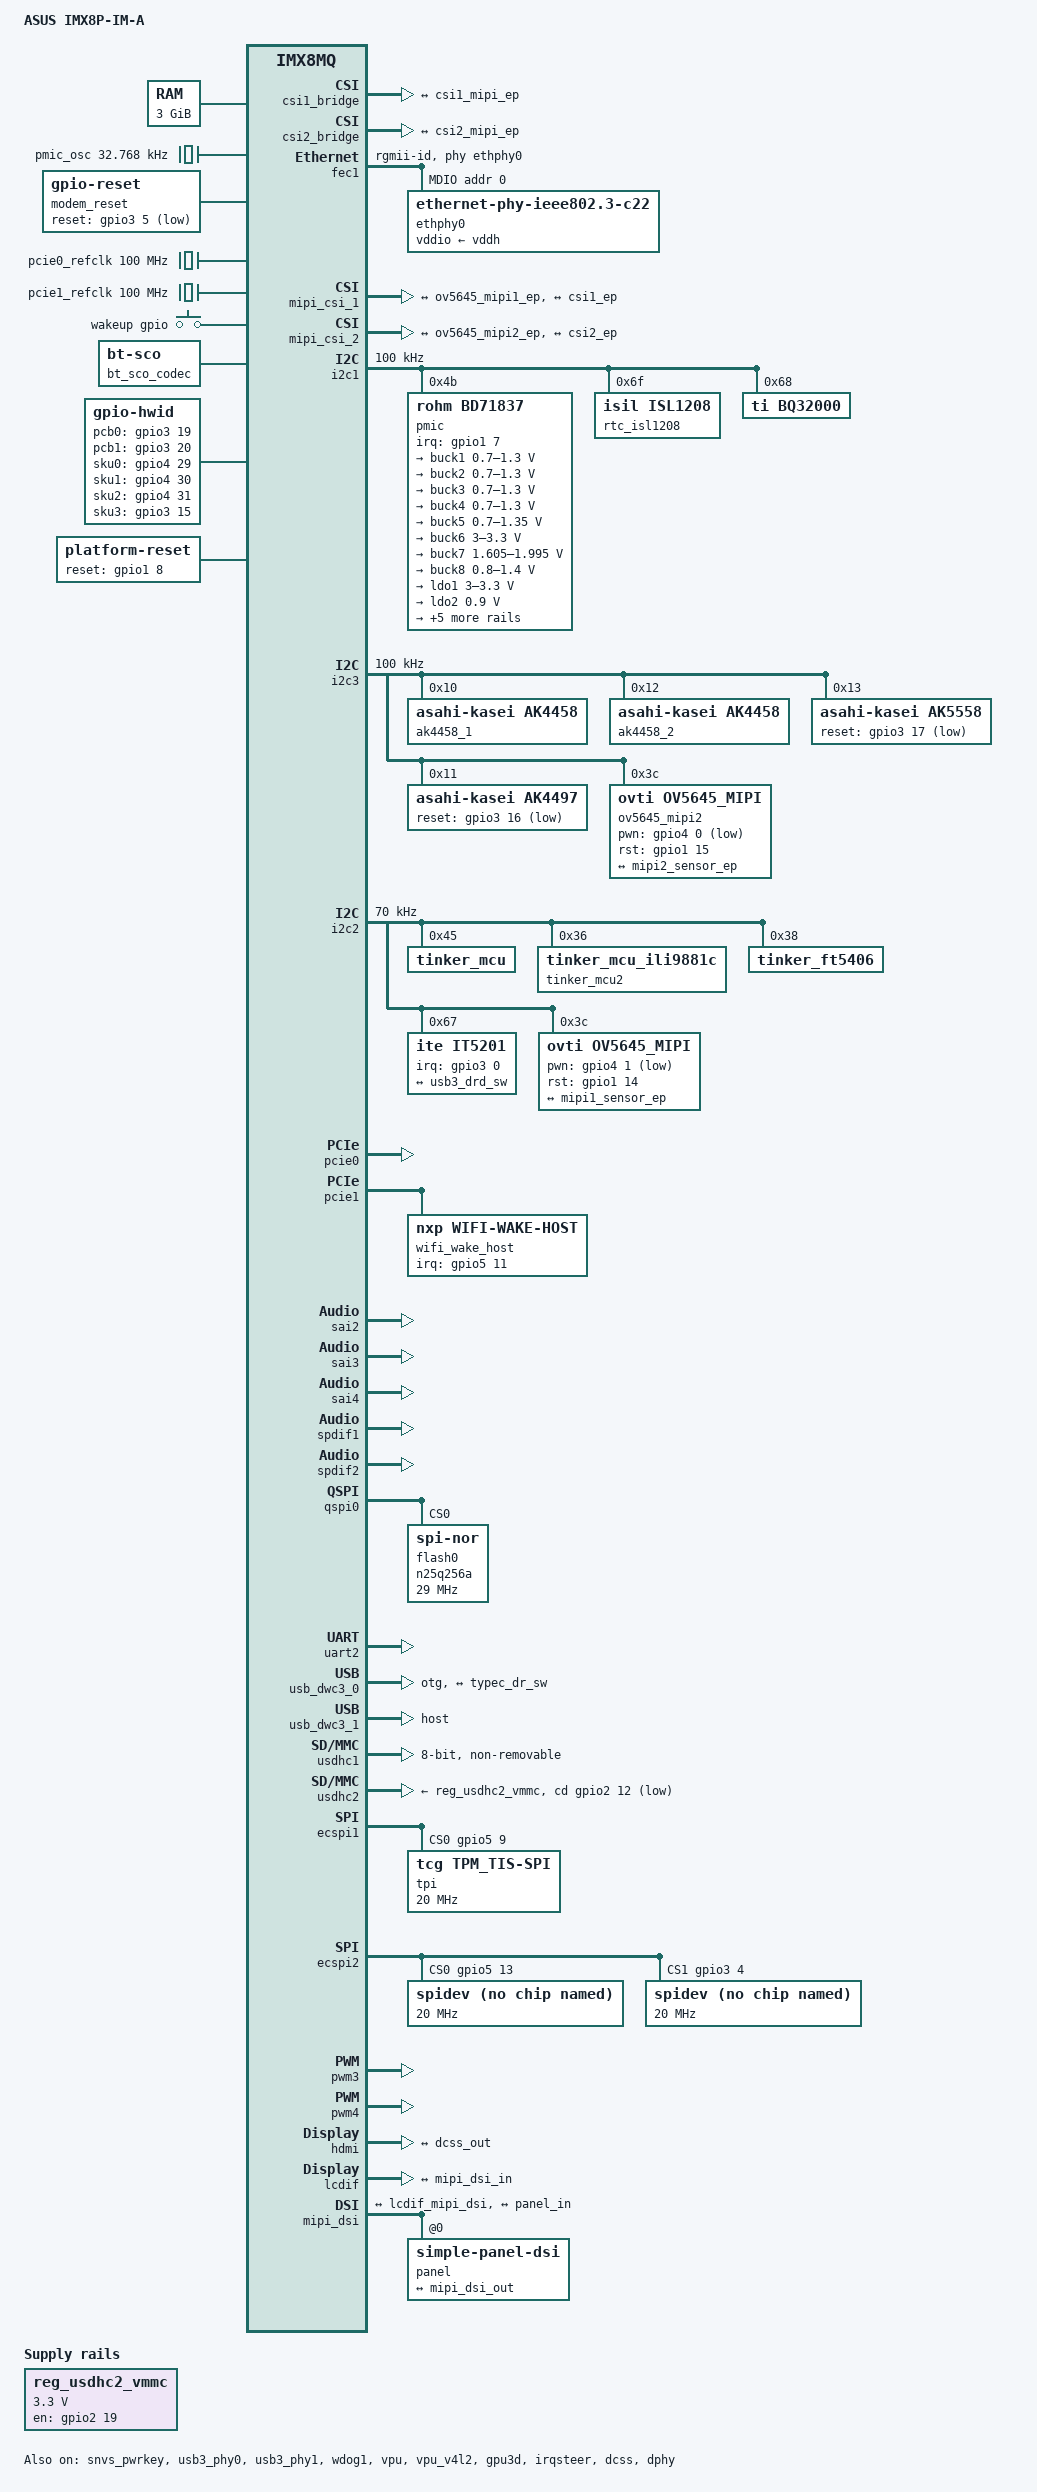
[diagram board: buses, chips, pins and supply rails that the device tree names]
// SPDX-License-Identifier: (GPL-2.0 OR MIT)
/*
 * Copyright 2017 NXP
 * Copyright (C) 2017-2018 Pengutronix, Lucas Stach <kernel@pengutronix.de>
 */

/dts-v1/;

#include <dt-bindings/usb/pd.h>
#include "imx8mq.dtsi"

/ {
	model = "ASUS IMX8P-IM-A";
	compatible = "fsl,imx8mq-evk", "fsl,imx8mq";

        aliases {
                rtc0 = &snvs_rtc;
                rtc1 = &bq32000;
                rtc2 = &rtc_isl1208;
        };

	chosen {
		stdout-path = &uart1;
	};

	memory@40000000 {
		device_type = "memory";
		reg = <0x00000000 0x40000000 0 0xc0000000>;
	};

	pmic_osc: clock-pmic {
		compatible = "fixed-clock";
		#clock-cells = <0>;
		clock-frequency = <32768>;
		clock-output-names = "pmic_osc";
	};

	modem_reset: modem-reset {
		compatible = "gpio-reset";
		reset-gpios = <&gpio3 5 GPIO_ACTIVE_LOW>;
		reset-delay-us = <2000>;
		reset-post-delay-ms = <40>;
		#reset-cells = <0>;
	};

	resmem: reserved-memory {
		#address-cells = <2>;
		#size-cells = <2>;
		ranges;

		/* global autoconfigured region for contiguous allocations */
		linux,cma {
			compatible = "shared-dma-pool";
			reusable;
			size = <0 0x38000000>;
			alloc-ranges = <0 0x80000000 0 0x38000000>;
			linux,cma-default;
		};
	};

	pcie0_refclk: pcie0-refclk {
		compatible = "fixed-clock";
		#clock-cells = <0>;
		clock-frequency = <100000000>;
	};

	pcie1_refclk: pcie0-refclk {
		compatible = "fixed-clock";
		#clock-cells = <0>;
		clock-frequency = <100000000>;
	};

	reg_usdhc2_vmmc: regulator-vsd-3v3 {
		pinctrl-names = "default";
		pinctrl-0 = <&pinctrl_reg_usdhc2>;
		compatible = "regulator-fixed";
		regulator-name = "VSD_3V3";
		regulator-min-microvolt = <3300000>;
		regulator-max-microvolt = <3300000>;
		gpio = <&gpio2 19 GPIO_ACTIVE_HIGH>;
		off-on-delay-us = <20000>;
		enable-active-high;
	};

	gpio-keys {
		compatible = "gpio-keys";
		wakeup {
			label = "wakeup gpio";
			gpio = <&gpio1 12 GPIO_ACTIVE_LOW>;
			linux,code = <KEY_WAKEUP>;
			gpio-key,wakeup;
		};
	};

	ir-receiver {
		compatible = "gpio-ir-receiver";
		gpios = <&gpio1 12 GPIO_ACTIVE_LOW>;
		pinctrl-names = "default";
		pinctrl-0 = <&pinctrl_ir>;
		linux,autosuspend-period = <125>;
		status = "disabled";
	};

	bt_sco_codec: bt_sco_codec {
		#sound-dai-cells = <1>;
		compatible = "linux,bt-sco";
	};

	wm8524: audio-codec {
		#sound-dai-cells = <0>;
		compatible = "wlf,wm8524";
		wlf,mute-gpios = <&gpio1 8 GPIO_ACTIVE_LOW>;
		status = "disabled";
	};

	sound-bt-sco {
		compatible = "simple-audio-card";
		simple-audio-card,name = "bt-sco-audio";
		simple-audio-card,format = "dsp_a";
		simple-audio-card,bitclock-inversion;
		simple-audio-card,frame-master = <&btcpu>;
		simple-audio-card,bitclock-master = <&btcpu>;

		btcpu: simple-audio-card,cpu {
			sound-dai = <&sai3>;
			dai-tdm-slot-num = <2>;
			dai-tdm-slot-width = <16>;
		};

		simple-audio-card,codec {
			sound-dai = <&bt_sco_codec 1>;
		};
	};

	sound-wm8524 {
		compatible = "simple-audio-card";
		simple-audio-card,name = "wm8524-audio";
		simple-audio-card,format = "i2s";
		simple-audio-card,frame-master = <&cpudai>;
		simple-audio-card,bitclock-master = <&cpudai>;
		simple-audio-card,widgets =
			"Line", "Left Line Out Jack",
			"Line", "Right Line Out Jack";
		simple-audio-card,routing =
			"Left Line Out Jack", "LINEVOUTL",
			"Right Line Out Jack", "LINEVOUTR";

		cpudai: simple-audio-card,cpu {
			sound-dai = <&sai2>;
			dai-tdm-slot-num = <2>;
			dai-tdm-slot-width = <32>;
		};

		link_codec: simple-audio-card,codec {
			sound-dai = <&wm8524>;
			clocks = <&clk IMX8MQ_CLK_SAI2_ROOT>;
		};
	};

	sound-hdmi {
		compatible = "fsl,imx-audio-hdmi";
		model = "imx-audio-hdmi";
		audio-cpu = <&sai4>;
		hdmi-out;
		constraint-rate = <44100>,
				<88200>,
				<176400>,
				<32000>,
				<48000>,
				<96000>,
				<192000>;
	};

	sound-spdif {
		compatible = "fsl,imx-audio-spdif";
		model = "imx-spdif";
		spdif-controller = <&spdif1>;
		spdif-out;
		spdif-in;
	};

	sound-hdmi-arc {
		compatible = "fsl,imx-audio-spdif";
		model = "imx-hdmi-arc";
		spdif-controller = <&spdif2>;
		spdif-in;
	};

	sound-ak4458 {
		compatible = "fsl,imx-audio-card";
		model = "ak4458-audio";
		pri-dai-link {
			link-name = "akcodec";
			format = "i2s";
			cpu {
				sound-dai = <&sai1>;
			};
			codec {
				sound-dai = <&ak4458_1>, <&ak4458_2>;
			};
		};
	};

	sound-ak5558 {
		compatible = "fsl,imx-audio-card";
		model = "ak5558-audio";
		pri-dai-link {
			link-name = "akcodec";
			format = "i2s";
			cpu {
				sound-dai = <&sai5>;
			};
			codec {
				sound-dai = <&ak5558>;
			};
		};
	};

	sound-ak4497 {
		compatible = "fsl,imx-audio-card";
		model = "ak4497-audio";
		status = "disabled";
		pri-dai-link {
			link-name = "akcodec";
			format = "i2s";
			cpu {
				sound-dai = <&sai1>;
			};
			codec {
				sound-dai = <&ak4497>;
			};
		};
	};

	hwid: gpio-hwid {
		compatible = "gpio-hwid";
		boardinfo = "IMX8P-IM-A";
		pcb0-gpios = <&gpio3 19 GPIO_ACTIVE_HIGH>;
		pcb1-gpios = <&gpio3 20 GPIO_ACTIVE_HIGH>;
		sku0-gpios = <&gpio4 29 GPIO_ACTIVE_HIGH>;
		sku1-gpios = <&gpio4 30 GPIO_ACTIVE_HIGH>;
		sku2-gpios = <&gpio4 31 GPIO_ACTIVE_HIGH>;
		sku3-gpios = <&gpio3 15 GPIO_ACTIVE_HIGH>;
	};
	
	platform-reset {
		compatible = "platform-reset";
		reset-gpio = <&gpio1 8 GPIO_ACTIVE_HIGH>;
	};

	backlight_dsi: backlight_dsi {
		compatible = "pwm-backlight";
		pwms = <&pwm4 0 400000>;
		status = "disabled";
		pinctrl-names = "default";
		pinctrl-0 = <&pinctrl_dsi>;
		soc_enablekl-gpios = <&gpio3 24 GPIO_ACTIVE_HIGH>;
		default-brightness-level = <200>;
		minimal-brightness-level = <30>;

		brightness-levels = <
				0   1   2   3   4   5   6   7
				8   9   10  11  12  13  14  15
				16  17  18  19  20  21  22  23
				24  25  26  27  28  29  30  31
				32  33  34  35  36  37  38  39
				40  41  42  43  44  45  46  47
				48  49  50  51  52  53  54  55
				56  57  58  59  60  61  62  63
				64  65  66  67  68  69  70  71
				72  73  74  75  76  77  78  79
				80  81  82  83  84  85  86  87
				88  89  90  91  92  93  94  95
				96  97  98  99  100 101 102 103
				104 105 106 107 108 109 110 111
				112 113 114 115 116 117 118 119
				120 121 122 123 124 125 126 127
				128 129 130 131 132 133 134 135
				136 137 138 139 140 141 142 143
				144 145 146 147 148 149 150 151
				152 153 154 155 156 157 158 159
				160 161 162 163 164 165 166 167
				168 169 170 171 172 173 174 175
				176 177 178 179 180 181 182 183
				184 185 186 187 188 189 190 191
				192 193 194 195 196 197 198 199
				200 201 202 203 204 205 206 207
				208 209 210 211 212 213 214 215
				216 217 218 219 220 221 222 223
				224 225 226 227 228 229 230 231
				232 233 234 235 236 237 238 239
				240 241 242 243 244 245 246 247
				248 249 250 251 252 253 254 255
		>;
	};
};

&ocotp {
	read-only;
};

&A53_0 {
	cpu-supply = <&buck2>;
};

&A53_1 {
	cpu-supply = <&buck2>;
};

&A53_2 {
	cpu-supply = <&buck2>;
};

&A53_3 {
	cpu-supply = <&buck2>;
};

&csi1_bridge {
	fsl,mipi-mode;
	fsl,two-8bit-sensor-mode;
	status = "okay";

	port {
		csi1_ep: endpoint {
			remote-endpoint = <&csi1_mipi_ep>;
		};
	};
};

&csi2_bridge {
	fsl,mipi-mode;
	fsl,two-8bit-sensor-mode;
	status = "okay";

	port {
		csi2_ep: endpoint {
			remote-endpoint = <&csi2_mipi_ep>;
		};
	};
};

&ddrc {
	operating-points-v2 = <&ddrc_opp_table>;

	ddrc_opp_table: opp-table {
		compatible = "operating-points-v2";

		opp-25M {
			opp-hz = /bits/ 64 <25000000>;
		};

		opp-100M {
			opp-hz = /bits/ 64 <100000000>;
		};

		/*
		 * On imx8mq B0 PLL can't be bypassed so low bus is 166M
		 */
		opp-166M {
			opp-hz = /bits/ 64 <166935483>;
		};

		opp-800M {
			opp-hz = /bits/ 64 <800000000>;
		};
	};
};

&fec1 {
	pinctrl-names = "default";
	pinctrl-0 = <&pinctrl_fec1>;
	phy-mode = "rgmii-id";
	phy-handle = <&ethphy0>;
	fsl,magic-packet;
	status = "okay";

	mdio {
		#address-cells = <1>;
		#size-cells = <0>;

		ethphy0: ethernet-phy@0 {
			compatible = "ethernet-phy-ieee802.3-c22";
			reg = <0>;
			qca,disable-smarteee;
			vddio-supply = <&vddh>;

			vddh: vddh-regulator {
			};
		};
	};
};

&mipi_csi_1 {
	#address-cells = <1>;
	#size-cells = <0>;
	status = "okay";
	port {
		mipi1_sensor_ep: endpoint@0 {
			remote-endpoint = <&ov5645_mipi1_ep>;
			data-lanes = <1 2>;
			bus-type = <4>;
		};

		csi1_mipi_ep: endpoint@1 {
			remote-endpoint = <&csi1_ep>;
		};
	};
};

&mipi_csi_2 {
	#address-cells = <1>;
	#size-cells = <0>;
	status = "okay";
	port {
		mipi2_sensor_ep: endpoint@0 {
			remote-endpoint = <&ov5645_mipi2_ep>;
			data-lanes = <1 2>;
			bus-type = <4>;
		};

		csi2_mipi_ep: endpoint@1 {
			remote-endpoint = <&csi2_ep>;
		};
	};
};

&i2c1 {
	clock-frequency = <100000>;
	pinctrl-names = "default";
	pinctrl-0 = <&pinctrl_i2c1>;
	status = "okay";

	ov5640_mipi2: ov5640_mipi2@3c {
		compatible = "ovti,ov5640_mipi";
		reg = <0x3c>;
		status = "disabled";
		pinctrl-names = "default";
		pinctrl-0 = <&pinctrl_csi2_pwn>, <&pinctrl_csi_rst>;
		clocks = <&clk IMX8MQ_CLK_CLKO2>;
		clock-names = "csi_mclk";
		assigned-clocks = <&clk IMX8MQ_CLK_CLKO2>;
		assigned-clock-parents = <&clk IMX8MQ_SYS2_PLL_200M>;
		assigned-clock-rates = <20000000>;
		csi_id = <1>;
		pwn-gpios = <&gpio1 5 GPIO_ACTIVE_HIGH>;
		mclk = <20000000>;
		mclk_source = <0>;
		port {
			ov5640_mipi2_ep: endpoint {
				remote-endpoint = <&mipi2_sensor_ep>;
			};
		};
	};

	pmic: bd71837@4b {
		compatible = "rohm,bd71837";
		reg = <0x4b>;
		pinctrl-names = "default";
		pinctrl-0 = <&pinctrl_pmic>;
		#clock-cells = <0>;
		clocks = <&pmic_osc>;
		clock-output-names = "pmic_clk";
		interrupt-parent = <&gpio1>;
		interrupts = <7 IRQ_TYPE_LEVEL_LOW>;
		rohm,reset-snvs-powered;

		regulators {
			buck1: BUCK1 {
				regulator-name = "buck1";
				regulator-min-microvolt = <700000>;
				regulator-max-microvolt = <1300000>;
				regulator-boot-on;
				regulator-always-on;
				regulator-ramp-delay = <1250>;
			};

			buck2: BUCK2 {
				regulator-name = "buck2";
				regulator-min-microvolt = <700000>;
				regulator-max-microvolt = <1300000>;
				regulator-boot-on;
				regulator-always-on;
			};

			buck3: BUCK3 {
				regulator-name = "buck3";
				regulator-min-microvolt = <700000>;
				regulator-max-microvolt = <1300000>;
				regulator-boot-on;
			};

			buck4: BUCK4 {
				regulator-name = "buck4";
				regulator-min-microvolt = <700000>;
				regulator-max-microvolt = <1300000>;
				regulator-boot-on;
				regulator-always-on;
			};

			buck5: BUCK5 {
				regulator-name = "buck5";
				regulator-min-microvolt = <700000>;
				regulator-max-microvolt = <1350000>;
				regulator-boot-on;
				regulator-always-on;
			};

			buck6: BUCK6 {
				regulator-name = "buck6";
				regulator-min-microvolt = <3000000>;
				regulator-max-microvolt = <3300000>;
				regulator-boot-on;
				regulator-always-on;
			};

			buck7: BUCK7 {
				regulator-name = "buck7";
				regulator-min-microvolt = <1605000>;
				regulator-max-microvolt = <1995000>;
				regulator-boot-on;
				regulator-always-on;
			};

			buck8: BUCK8 {
				regulator-name = "buck8";
				regulator-min-microvolt = <800000>;
				regulator-max-microvolt = <1400000>;
				regulator-boot-on;
				regulator-always-on;
			};

			ldo1: LDO1 {
				regulator-name = "ldo1";
				regulator-min-microvolt = <3000000>;
				regulator-max-microvolt = <3300000>;
				regulator-boot-on;
				regulator-always-on;
			};

			ldo2: LDO2 {
				regulator-name = "ldo2";
				regulator-min-microvolt = <900000>;
				regulator-max-microvolt = <900000>;
				regulator-boot-on;
				regulator-always-on;
			};

			ldo3: LDO3 {
				regulator-name = "ldo3";
				regulator-min-microvolt = <1800000>;
				regulator-max-microvolt = <3300000>;
				regulator-boot-on;
				regulator-always-on;
			};

			ldo4: LDO4 {
				regulator-name = "ldo4";
				regulator-min-microvolt = <900000>;
				regulator-max-microvolt = <1800000>;
				regulator-boot-on;
				regulator-always-on;
			};

			ldo5: LDO5 {
				regulator-name = "ldo5";
				regulator-min-microvolt = <1800000>;
				regulator-max-microvolt = <3300000>;
				regulator-boot-on;
				regulator-always-on;
			};

			ldo6: LDO6 {
				regulator-name = "ldo6";
				regulator-min-microvolt = <900000>;
				regulator-max-microvolt = <1800000>;
				regulator-boot-on;
				regulator-always-on;
			};

			ldo7: LDO7 {
				regulator-name = "ldo7";
				regulator-min-microvolt = <1800000>;
				regulator-max-microvolt = <3300000>;
				regulator-boot-on;
				regulator-always-on;
			};
		};
	};

	rtc_isl1208: rtc@6f {
		compatible = "isil,isl1208";
		reg = <0x6f>;
		status = "okay";
	};

        bq32000: rtc@68 {
                compatible = "ti,bq32000";
                reg = <0x68>;
        };
};

&i2c3 {
	clock-frequency = <100000>;
	pinctrl-names = "default";
	pinctrl-0 = <&pinctrl_i2c3>;
	status = "okay";

	synaptics_dsx_ts: synaptics_dsx_ts@20 {
		compatible = "synaptics_dsx";
		reg = <0x20>;
		pinctrl-names = "default";
		pinctrl-0 = <&pinctrl_i2c1_dsi_ts_int>;
		interrupt-parent = <&gpio5>;
		interrupts = <7 IRQ_TYPE_LEVEL_LOW>;
		synaptics,diagonal-rotation;
		status = "disabled";
	};

	ak4458_1: ak4458@10 {
		#sound-dai-cells = <0>;
		sound-name-prefix = "0";
		compatible = "asahi-kasei,ak4458";
		reg = <0x10>;
	};

	ak4458_2: ak4458@12 {
		#sound-dai-cells = <0>;
		sound-name-prefix = "1";
		compatible = "asahi-kasei,ak4458";
		reg = <0x12>;
	};

	ak5558: ak5558@13 {
		#sound-dai-cells = <0>;
		compatible = "asahi-kasei,ak5558";
		reg = <0x13>;
		reset-gpios = <&gpio3 17 GPIO_ACTIVE_LOW>;
	};

	ak4497: ak4497@11 {
		#sound-dai-cells = <0>;
		compatible = "asahi-kasei,ak4497";
		reg = <0x11>;
		reset-gpios = <&gpio3 16 GPIO_ACTIVE_LOW>;
		dsd-path = <1>;
	};

	adv_bridge: adv7535@3d {
		compatible = "adi,adv7535";
		reg = <0x3d>;
		adi,addr-cec = <0x3b>;
		adi,dsi-lanes = <4>;
		pinctrl-0 = <&pinctrl_i2c1_dsi_ts_int>;
		interrupt-parent = <&gpio5>;
		interrupts = <7 IRQ_TYPE_LEVEL_LOW>;

		status = "disabled";
	};

	ov5645_mipi2: ov5645_mipi@3c {
		compatible = "ovti,ov5645_mipi";
		reg = <0x3c>;
		status = "okay";
		pinctrl-names = "default";
		pinctrl-0 = <&pinctrl_csi2_pwn>;
		clocks = <&clk IMX8MQ_CLK_CLKO2>;
		clock-names = "csi_mclk";
		csi_id = <1>;
		pwn-gpios = <&gpio4 0 1>;
		rst-gpios = <&gpio1 15 0>;
		mclk = <20000000>;
		mclk_source = <0>;
		ae_target = <52>;
		port {
			ov5645_mipi2_ep: endpoint {
				remote-endpoint = <&mipi2_sensor_ep>;
			};
		};
	};

};

&i2c2 {
	clock-frequency = <70000>;
	pinctrl-names = "default";
	pinctrl-0 = <&pinctrl_i2c2>;
	status = "okay";

	tinker_mcu: tinker_mcu@45 {
		status = "okay";
		compatible = "tinker_mcu";
		reg = <0x45>;
	};

	tinker_mcu2: tinker_mcu2@36 {
		status = "okay";
		compatible = "tinker_mcu_ili9881c";
		reg = <0x36>;
	};

	tinker_ft5406: tinker_ft5406@38 {
		compatible = "tinker_ft5406";
		reg = <0x38>;
	};

	ov5640_mipi: ov5640_mipi@3c {
		compatible = "ovti,ov5640_mipi";
		reg = <0x3c>;
		status = "disabled";
		pinctrl-names = "default";
		pinctrl-0 = <&pinctrl_csi1_pwn>;
		clocks = <&clk IMX8MQ_CLK_CLKO2>;
		clock-names = "csi_mclk";
		assigned-clocks = <&clk IMX8MQ_CLK_CLKO2>;
		assigned-clock-parents = <&clk IMX8MQ_SYS2_PLL_200M>;
		assigned-clock-rates = <20000000>;
		csi_id = <0>;
		pwn-gpios = <&gpio1 3 GPIO_ACTIVE_HIGH>;
		mclk = <20000000>;
		mclk_source = <0>;
		port {
			ov5640_mipi1_ep: endpoint {
				remote-endpoint = <&mipi1_sensor_ep>;
			};
		};
	};

	it5201: tcpc@67 {
		compatible = "ite,it5201";
		pinctrl-names = "default";
		pinctrl-0 = <&pinctrl_typec>;
		reg = <0x67>;
		interrupt-parent = <&gpio3>;
		interrupts = <0 IRQ_TYPE_EDGE_FALLING>;
		port {
			typec_dr_sw: endpoint {
				remote-endpoint = <&usb3_drd_sw>;
			};
		};
	};

	ov5645_mipi: ov5645_mipi@3c {
		compatible = "ovti,ov5645_mipi";
		reg = <0x3c>;
		status = "okay";
		pinctrl-names = "default";
		pinctrl-0 = <&pinctrl_csi1_pwn>;
		clocks = <&clk IMX8MQ_CLK_CLKO2>;
		clock-names = "csi_mclk";
		csi_id = <0>;
		pwn-gpios = <&gpio4 1 1>;
		rst-gpios = <&gpio1 14 0>;
		mclk = <20000000>;
		mclk_source = <0>;
		ae_target = <52>;
		port {
			ov5645_mipi1_ep: endpoint {
				remote-endpoint = <&mipi1_sensor_ep>;
			};
		};
	};

};

&pcie0 {
	pinctrl-names = "default";
	pinctrl-0 = <&pinctrl_pcie0>;
	clocks = <&clk IMX8MQ_CLK_PCIE1_ROOT>,
		 <&clk IMX8MQ_CLK_PCIE1_AUX>,
		 <&clk IMX8MQ_CLK_PCIE1_PHY>,
		 <&pcie0_refclk>;
	clock-names = "pcie", "pcie_aux", "pcie_phy", "pcie_bus";
	//vph-supply = <&vgen5_reg>;
	assigned-clocks = <&clk IMX8MQ_CLK_PCIE1_AUX>,
			  <&clk IMX8MQ_CLK_PCIE1_PHY>,
			  <&clk IMX8MQ_CLK_PCIE1_CTRL>;
	assigned-clock-rates = <10000000>, <100000000>, <250000000>;
	assigned-clock-parents = <&clk IMX8MQ_SYS2_PLL_50M>,
				 <&clk IMX8MQ_SYS2_PLL_100M>,
				 <&clk IMX8MQ_SYS2_PLL_250M>;
	hard-wired = <1>;
	//vph-supply = <&vgen5_reg>;
	l1ss-disabled;
	status = "okay";
};

&pcie1 {
	clocks = <&clk IMX8MQ_CLK_PCIE2_ROOT>,
		 <&clk IMX8MQ_CLK_PCIE2_AUX>,
		 <&clk IMX8MQ_CLK_PCIE2_PHY>,
		 <&pcie1_refclk>;
	clock-names = "pcie", "pcie_aux", "pcie_phy", "pcie_bus";
	assigned-clocks = <&clk IMX8MQ_CLK_PCIE2_AUX>,
			  <&clk IMX8MQ_CLK_PCIE1_PHY>,
			  <&clk IMX8MQ_CLK_PCIE1_CTRL>;
	assigned-clock-rates = <10000000>, <100000000>, <250000000>;
	assigned-clock-parents = <&clk IMX8MQ_SYS2_PLL_50M>,
				 <&clk IMX8MQ_SYS2_PLL_100M>,
				 <&clk IMX8MQ_SYS2_PLL_250M>;
	//vph-supply = <&vgen5_reg>;
	l1ss-disabled;
	status = "okay";

	wifi_wake_host {
		compatible = "nxp,wifi-wake-host";
		interrupt-parent = <&gpio5>;
		interrupts = <11 IRQ_TYPE_LEVEL_LOW>;
		interrupt-names = "host-wake";
	};
};

&pcie1_ep {
	clocks = <&clk IMX8MQ_CLK_PCIE2_ROOT>,
		 <&clk IMX8MQ_CLK_PCIE2_AUX>,
		 <&clk IMX8MQ_CLK_PCIE2_PHY>,
		 <&pcie1_refclk>;
	clock-names = "pcie", "pcie_aux", "pcie_phy", "pcie_bus";
	assigned-clocks = <&clk IMX8MQ_CLK_PCIE2_AUX>,
			  <&clk IMX8MQ_CLK_PCIE1_PHY>,
			  <&clk IMX8MQ_CLK_PCIE1_CTRL>;
	assigned-clock-rates = <10000000>, <100000000>, <250000000>;
	assigned-clock-parents = <&clk IMX8MQ_SYS2_PLL_50M>,
				 <&clk IMX8MQ_SYS2_PLL_100M>,
				 <&clk IMX8MQ_SYS2_PLL_250M>;
	status = "disabled";
};

&pgc_gpu {
	power-supply = <&buck3>;
};

&pgc_vpu {
	power-supply = <&buck4>;
};

&sai1 {
	pinctrl-names = "default", "pcm_b2m", "dsd";
	pinctrl-0 = <&pinctrl_sai1_pcm>;
	pinctrl-1 = <&pinctrl_sai1_pcm_b2m>;
	pinctrl-2 = <&pinctrl_sai1_dsd>;
	assigned-clocks = <&clk IMX8MQ_CLK_SAI1>;
	assigned-clock-parents = <&clk IMX8MQ_AUDIO_PLL1_OUT>;
	assigned-clock-rates = <49152000>;
	clocks = <&clk IMX8MQ_CLK_SAI1_IPG>, <&clk IMX8MQ_CLK_DUMMY>,
		<&clk IMX8MQ_CLK_SAI1_ROOT>, <&clk IMX8MQ_CLK_DUMMY>,
		<&clk IMX8MQ_CLK_DUMMY>, <&clk IMX8MQ_AUDIO_PLL1_OUT>,
		<&clk IMX8MQ_AUDIO_PLL2_OUT>;
	clock-names = "bus", "mclk0", "mclk1", "mclk2", "mclk3", "pll8k", "pll11k";
	fsl,sai-multi-lane;
	fsl,dataline,dsd = <0 0xff 0xff 2 0xff 0x11>;
	dmas = <&sdma2 8 25 0>, <&sdma2 9 25 0>;
	status = "disabled";
};

&sai2 {
	pinctrl-names = "default";
	pinctrl-0 = <&pinctrl_sai2>;
	assigned-clocks = <&clk IMX8MQ_CLK_SAI2>;
	assigned-clock-parents = <&clk IMX8MQ_AUDIO_PLL1_OUT>;
	assigned-clock-rates = <24576000>;
	status = "okay";
};

&sai3 {
	#sound-dai-cells = <0>;
	pinctrl-names = "default";
	pinctrl-0 = <&pinctrl_sai3>;
	assigned-clocks = <&clk IMX8MQ_CLK_SAI3>;
	assigned-clock-parents = <&clk IMX8MQ_AUDIO_PLL1_OUT>;
	assigned-clock-rates = <24576000>;
	status = "okay";
};

&sai4 {
	assigned-clocks = <&clk IMX8MQ_CLK_SAI4>;
	assigned-clock-parents = <&clk IMX8MQ_AUDIO_PLL1_OUT>;
	assigned-clock-rates = <24576000>;
	clocks = <&clk IMX8MQ_CLK_SAI4_IPG>, <&clk IMX8MQ_CLK_DUMMY>,
		<&clk IMX8MQ_CLK_SAI4_ROOT>, <&clk IMX8MQ_CLK_DUMMY>,
		<&clk IMX8MQ_CLK_DUMMY>, <&clk IMX8MQ_AUDIO_PLL1_OUT>,
		<&clk IMX8MQ_AUDIO_PLL2_OUT>;
	clock-names = "bus", "mclk0", "mclk1", "mclk2", "mclk3", "pll8k", "pll11k";
	fsl,sai-multi-lane;
	dmas = <&sdma2 0 25 0>, <&sdma2 1 25 0>;
	status = "okay";
};

&sai5 {
	pinctrl-names = "default";
	pinctrl-0 = <&pinctrl_sai5>;
	assigned-clocks = <&clk IMX8MQ_CLK_SAI5>;
	assigned-clock-parents = <&clk IMX8MQ_AUDIO_PLL1_OUT>;
	assigned-clock-rates = <49152000>;
	clocks = <&clk IMX8MQ_CLK_SAI5_IPG>, <&clk IMX8MQ_CLK_DUMMY>,
		<&clk IMX8MQ_CLK_SAI5_ROOT>, <&clk IMX8MQ_CLK_DUMMY>,
		<&clk IMX8MQ_CLK_DUMMY>, <&clk IMX8MQ_AUDIO_PLL1_OUT>,
		<&clk IMX8MQ_AUDIO_PLL2_OUT>;
	clock-names = "bus", "mclk0", "mclk1", "mclk2", "mclk3", "pll8k", "pll11k";
	fsl,sai-asynchronous;
	fsl,sai-multi-lane;
	dmas = <&sdma2 2 25 0>, <&sdma2 3 25 0>;
	status = "disabled";
};

&snvs_pwrkey {
	status = "okay";
};

&spdif1 {
	pinctrl-names = "default";
	pinctrl-0 = <&pinctrl_spdif1>;
	assigned-clocks = <&clk IMX8MQ_CLK_SPDIF1>;
	assigned-clock-parents = <&clk IMX8MQ_AUDIO_PLL1_OUT>;
	assigned-clock-rates = <24576000>;
	clocks = <&clk IMX8MQ_CLK_IPG_ROOT>, <&clk IMX8MQ_CLK_25M>,
		<&clk IMX8MQ_CLK_SPDIF1>, <&clk IMX8MQ_CLK_DUMMY>,
		<&clk IMX8MQ_CLK_DUMMY>, <&clk IMX8MQ_CLK_DUMMY>,
		<&clk IMX8MQ_CLK_IPG_ROOT>, <&clk IMX8MQ_CLK_DUMMY>,
		<&clk IMX8MQ_CLK_DUMMY>, <&clk IMX8MQ_CLK_DUMMY>,
		<&clk IMX8MQ_AUDIO_PLL1_OUT>, <&clk IMX8MQ_AUDIO_PLL2_OUT>;
	clock-names = "core", "rxtx0", "rxtx1", "rxtx2", "rxtx3", "rxtx4",
		      "rxtx5", "rxtx6", "rxtx7", "spba", "pll8k", "pll11k";
	status = "okay";
};

&spdif2 {
	assigned-clocks = <&clk IMX8MQ_CLK_SPDIF2>;
	assigned-clock-parents = <&clk IMX8MQ_AUDIO_PLL1_OUT>;
	assigned-clock-rates = <24576000>;
	status = "okay";
};

&qspi0 {
	pinctrl-names = "default";
	pinctrl-0 = <&pinctrl_qspi>;
	status = "okay";

	flash0: n25q256a@0 {
		reg = <0>;
		#address-cells = <1>;
		#size-cells = <1>;
		compatible = "jedec,spi-nor";
		spi-max-frequency = <29000000>;
		spi-tx-bus-width = <1>;
		spi-rx-bus-width = <4>;
		spi-nor,ddr-quad-read-dummy = <6>;
	};
};

&uart1 {
	pinctrl-names = "default";
	pinctrl-0 = <&pinctrl_uart1>;
	assigned-clocks = <&clk IMX8MQ_CLK_UART1>;
	assigned-clock-parents = <&clk IMX8MQ_CLK_25M>;
	fsl,uart-has-rtscts;
	status = "disabled";
};

&uart2 {
	pinctrl-names = "default";
	pinctrl-0 = <&pinctrl_uart2>;
	assigned-clocks = <&clk IMX8MQ_CLK_UART2>;
	assigned-clock-parents = <&clk IMX8MQ_CLK_25M>;
	fsl,uart-has-rtscts;
	status = "okay";
};

&uart3 { /* BT */
	pinctrl-names = "default";
	pinctrl-0 = <&pinctrl_uart3>;
	assigned-clocks = <&clk IMX8MQ_CLK_UART3>;
	assigned-clock-parents = <&clk IMX8MQ_SYS1_PLL_80M>;
	fsl,uart-has-rtscts;
	resets = <&modem_reset>;
	status = "disabled";
};

&usb3_phy0 {
	status = "okay";
};

&usb_dwc3_0 {
	dr_mode = "otg";
	extcon = <&it5201>;
	snps,dis-u1-entry-quirk;
	snps,dis-u2-entry-quirk;
	status = "okay";

	port {
		usb3_drd_sw: endpoint {
			remote-endpoint = <&typec_dr_sw>;
		};
	};
};

&usb3_phy1 {
	status = "okay";
};

&usb_dwc3_1 {
	dr_mode = "host";
	status = "okay";
};

&usdhc1 {
	assigned-clocks = <&clk IMX8MQ_CLK_USDHC1>;
	assigned-clock-rates = <400000000>;
	pinctrl-names = "default", "state_100mhz", "state_200mhz";
	pinctrl-0 = <&pinctrl_usdhc1>;
	pinctrl-1 = <&pinctrl_usdhc1_100mhz>;
	pinctrl-2 = <&pinctrl_usdhc1_200mhz>;
	vqmmc-supply = <&buck7>;
	bus-width = <8>;
	non-removable;
	no-sd;
	no-sdio;
	status = "okay";
};

&usdhc2 {
	assigned-clocks = <&clk IMX8MQ_CLK_USDHC2>;
	assigned-clock-rates = <200000000>;
	pinctrl-names = "default", "state_100mhz", "state_200mhz";
	pinctrl-0 = <&pinctrl_usdhc2>, <&pinctrl_usdhc2_gpio>;
	pinctrl-1 = <&pinctrl_usdhc2_100mhz>, <&pinctrl_usdhc2_gpio>;
	pinctrl-2 = <&pinctrl_usdhc2_200mhz>, <&pinctrl_usdhc2_gpio>;
	cd-gpios = <&gpio2 12 GPIO_ACTIVE_LOW>;
	vmmc-supply = <&reg_usdhc2_vmmc>;
	status = "okay";
};

&wdog1 {
	pinctrl-names = "default";
	pinctrl-0 = <&pinctrl_wdog>;
	fsl,ext-reset-output;
	status = "okay";
};

&iomuxc {
	pinctrl-names = "default";
	pinctrl-0 = <&pinctrl_hog>;

	pinctrl_dsi: lkw070n1300-v2_bl_en_reset {
		fsl,pins = <
			MX8MQ_IOMUXC_SAI5_RXD2_GPIO3_IO23	0x19 /*RST*/
			MX8MQ_IOMUXC_SAI5_RXD3_GPIO3_IO24	0x19 /*BL_EN*/
		>;
	};

	pinctrl_hog: hoggrp {
		fsl,pins = <
			MX8MQ_IOMUXC_NAND_READY_B_GPIO3_IO16		0x19
			MX8MQ_IOMUXC_NAND_WE_B_GPIO3_IO17		0x19
			MX8MQ_IOMUXC_NAND_WP_B_GPIO3_IO18		0x19
			MX8MQ_IOMUXC_GPIO1_IO00_ANAMIX_REF_CLK_32K	0x16
			MX8MQ_IOMUXC_SAI5_RXFS_GPIO3_IO19		0x19
			MX8MQ_IOMUXC_SAI5_RXC_GPIO3_IO20		0x19
			MX8MQ_IOMUXC_SAI3_RXC_GPIO4_IO29		0x19
			MX8MQ_IOMUXC_SAI3_RXD_GPIO4_IO30		0x19
			MX8MQ_IOMUXC_SAI3_TXFS_GPIO4_IO31		0x19
			MX8MQ_IOMUXC_NAND_RE_B_GPIO3_IO15		0x19
			MX8MQ_IOMUXC_GPIO1_IO08_GPIO1_IO8		0x19 /* S_PLTRST */
			MX8MQ_IOMUXC_UART1_RXD_GPIO5_IO22		0x19
			MX8MQ_IOMUXC_UART1_TXD_GPIO5_IO23		0x19
		>;
	};

	pinctrl_buck2: vddarmgrp {
		fsl,pins = <
			MX8MQ_IOMUXC_GPIO1_IO13_GPIO1_IO13		0x19
		>;
	};

	pinctrl_csi1_pwn: csi1_pwn_grp {
		fsl,pins = <
			MX8MQ_IOMUXC_SAI1_RXC_GPIO4_IO1         0x19 /* PWDN */
			MX8MQ_IOMUXC_GPIO1_IO14_GPIO1_IO14      0x19 /* RESETB */
		>;
	};
	pinctrl_csi2_pwn: csi2_pwn_grp {
		fsl,pins = <
			MX8MQ_IOMUXC_SAI1_RXFS_GPIO4_IO0        0x19 /* PWDN */
			MX8MQ_IOMUXC_GPIO1_IO15_GPIO1_IO15      0x19 /* RESETB */
		>;
	};

	pinctrl_csi_rst: csi_rst_grp {
		fsl,pins = <
			MX8MQ_IOMUXC_GPIO1_IO06_GPIO1_IO6		0x19
			MX8MQ_IOMUXC_GPIO1_IO15_CCMSRCGPCMIX_CLKO2	0x59
		>;
	};

	pinctrl_ecspi1: ecspi1grp {
		fsl,pins = <
			MX8MQ_IOMUXC_ECSPI1_SCLK_ECSPI1_SCLK		0x82
			MX8MQ_IOMUXC_ECSPI1_MOSI_ECSPI1_MOSI		0x82
			MX8MQ_IOMUXC_ECSPI1_MISO_ECSPI1_MISO		0x82
			MX8MQ_IOMUXC_GPIO1_IO05_GPIO1_IO5		0x19
		>;
	};

	pinctrl_ecspi1_cs: ecspi1_cs_grp {
		fsl,pins = <
			MX8MQ_IOMUXC_ECSPI1_SS0_GPIO5_IO9		0x19
		>;
	};

	pinctrl_ecspi2: ecspi2grp {
		fsl,pins = <
			MX8MQ_IOMUXC_ECSPI2_SCLK_ECSPI2_SCLK		0x82
			MX8MQ_IOMUXC_ECSPI2_MOSI_ECSPI2_MOSI		0x82
			MX8MQ_IOMUXC_ECSPI2_MISO_ECSPI2_MISO		0x82
			MX8MQ_IOMUXC_GPIO1_IO03_GPIO1_IO3		0x19
		>;
	};

	pinctrl_ecspi2_cs: ecspi2_cs_grp {
		fsl,pins = <
			MX8MQ_IOMUXC_ECSPI2_SS0_GPIO5_IO13		0x19
			MX8MQ_IOMUXC_NAND_CE3_B_GPIO3_IO4		0x19
		>;
	};

	pinctrl_fec1: fec1grp {
		fsl,pins = <
			MX8MQ_IOMUXC_ENET_MDC_ENET1_MDC			0x7
			MX8MQ_IOMUXC_ENET_MDIO_ENET1_MDIO		0x7
			MX8MQ_IOMUXC_ENET_TD3_ENET1_RGMII_TD3		0x5
			MX8MQ_IOMUXC_ENET_TD2_ENET1_RGMII_TD2		0x5
			MX8MQ_IOMUXC_ENET_TD1_ENET1_RGMII_TD1		0x5
			MX8MQ_IOMUXC_ENET_TD0_ENET1_RGMII_TD0		0x5
			MX8MQ_IOMUXC_ENET_RD3_ENET1_RGMII_RD3		0x7
			MX8MQ_IOMUXC_ENET_RD2_ENET1_RGMII_RD2		0x7
			MX8MQ_IOMUXC_ENET_RD1_ENET1_RGMII_RD1		0x7
			MX8MQ_IOMUXC_ENET_RD0_ENET1_RGMII_RD0		0x7
			MX8MQ_IOMUXC_ENET_TXC_ENET1_RGMII_TXC		0x5
			MX8MQ_IOMUXC_ENET_RXC_ENET1_RGMII_RXC		0x7
			MX8MQ_IOMUXC_ENET_RX_CTL_ENET1_RGMII_RX_CTL	0x7
			MX8MQ_IOMUXC_ENET_TX_CTL_ENET1_RGMII_TX_CTL	0x5
			MX8MQ_IOMUXC_GPIO1_IO09_GPIO1_IO9		0x19
		>;
	};

	pinctrl_i2c1: i2c1grp {
		fsl,pins = <
			MX8MQ_IOMUXC_I2C1_SCL_I2C1_SCL			0x4000007f
			MX8MQ_IOMUXC_I2C1_SDA_I2C1_SDA			0x4000007f
		>;
	};

	pinctrl_ir: irgrp {
		fsl,pins = <
			MX8MQ_IOMUXC_GPIO1_IO12_GPIO1_IO12		0x4f
		>;
	};

	pinctrl_i2c3: i2c3grp {
		fsl,pins = <
			MX8MQ_IOMUXC_I2C3_SCL_I2C3_SCL			0x4000007f
			MX8MQ_IOMUXC_I2C3_SDA_I2C3_SDA			0x4000007f
		>;
	};

	pinctrl_i2c1_dsi_ts_int: dsi_ts_int {
		fsl,pins = <
			MX8MQ_IOMUXC_ECSPI1_MOSI_GPIO5_IO7		0x19
		>;
	};

	pinctrl_i2c3_dsi_ts_int: dsi_ts_int {
		fsl,pins = <
			MX8MQ_IOMUXC_ECSPI1_MOSI_GPIO5_IO7		0x59
		>;
	};

	pinctrl_i2c2: i2c2grp {
		fsl,pins = <
			MX8MQ_IOMUXC_I2C2_SCL_I2C2_SCL			0x40000067
			MX8MQ_IOMUXC_I2C2_SDA_I2C2_SDA			0x40000067
		>;
	};

	pinctrl_pcie0: pcie0grp {
		fsl,pins = <
			MX8MQ_IOMUXC_GPIO1_IO12_GPIO1_IO12		0x16 /* S_WAKE */
		>;
	};

	pinctrl_pmic: pmicirq {
		fsl,pins = <
			MX8MQ_IOMUXC_GPIO1_IO07_GPIO1_IO7		0x41
		>;
	};

	pinctrl_pwm3: pwm3 {
		fsl,pins = <
			MX8MQ_IOMUXC_SPDIF_TX_PWM3_OUT			0x7f
		>;
	};

	pinctrl_pwm4: pwm4 {
		fsl,pins = <
			MX8MQ_IOMUXC_SAI3_MCLK_PWM4_OUT			0x7f
		>;
	};

	pinctrl_qspi: qspigrp {
		fsl,pins = <
			MX8MQ_IOMUXC_NAND_CE0_B_QSPI_A_SS0_B	0x82
			MX8MQ_IOMUXC_NAND_DATA00_QSPI_A_DATA0	0x82
			MX8MQ_IOMUXC_NAND_DATA01_QSPI_A_DATA1	0x82
			MX8MQ_IOMUXC_NAND_DATA02_QSPI_A_DATA2	0x82
			MX8MQ_IOMUXC_NAND_DATA03_QSPI_A_DATA3	0x82
		>;
	};

	pinctrl_reg_usdhc2: regusdhc2gpiogrp {
		fsl,pins = <
			MX8MQ_IOMUXC_SD2_RESET_B_GPIO2_IO19		0x41
		>;
	};

	pinctrl_sai2: sai2grp {
		fsl,pins = <
			MX8MQ_IOMUXC_SAI2_TXFS_SAI2_TX_SYNC     0xd6
			MX8MQ_IOMUXC_SAI2_TXC_SAI2_TX_BCLK      0xd6
			MX8MQ_IOMUXC_SAI2_MCLK_SAI2_MCLK        0xd6
			MX8MQ_IOMUXC_SAI2_TXD0_SAI2_TX_DATA0    0xd6
			MX8MQ_IOMUXC_SAI2_RXD0_SAI2_RX_DATA0	0xd6
		>;
	};

	pinctrl_sai3: sai3grp {
		fsl,pins = <
			MX8MQ_IOMUXC_SAI3_TXFS_SAI3_TX_SYNC     0xd6
			MX8MQ_IOMUXC_SAI3_TXC_SAI3_TX_BCLK      0xd6
			MX8MQ_IOMUXC_SAI3_TXD_SAI3_TX_DATA0	0xd6
			MX8MQ_IOMUXC_SAI3_RXD_SAI3_RX_DATA0	0xd6
		>;
	};

	pinctrl_sai1_pcm: sai1grp_pcm {
		fsl,pins = <
			MX8MQ_IOMUXC_SAI1_MCLK_SAI1_MCLK		0xd6
			MX8MQ_IOMUXC_SAI1_TXFS_SAI1_TX_SYNC		0xd6
			MX8MQ_IOMUXC_SAI1_RXD7_SAI1_TX_SYNC		0xd6
			MX8MQ_IOMUXC_SAI1_TXC_SAI1_TX_BCLK		0xd6
			MX8MQ_IOMUXC_SAI1_TXD0_SAI1_TX_DATA0		0xd6
			MX8MQ_IOMUXC_SAI1_TXD1_SAI1_TX_DATA1		0xd6
			MX8MQ_IOMUXC_SAI1_TXD2_SAI1_TX_DATA2		0xd6
			MX8MQ_IOMUXC_SAI1_TXD3_SAI1_TX_DATA3		0xd6
			MX8MQ_IOMUXC_SAI1_TXD4_SAI1_TX_DATA4		0xd6
			MX8MQ_IOMUXC_SAI1_TXD5_SAI1_TX_DATA5		0xd6
			MX8MQ_IOMUXC_SAI1_TXD6_SAI1_TX_DATA6		0xd6
			MX8MQ_IOMUXC_SAI1_TXD7_SAI1_TX_DATA7		0xd6
		>;
	};

	pinctrl_sai1_pcm_b2m: sai1grp_pcm_b2m {
		fsl,pins = <
			MX8MQ_IOMUXC_SAI1_MCLK_SAI1_TX_BCLK		0xd6
			MX8MQ_IOMUXC_SAI1_TXFS_SAI1_TX_SYNC		0xd6
			MX8MQ_IOMUXC_SAI1_RXD7_SAI1_TX_SYNC		0xd6
			MX8MQ_IOMUXC_SAI1_TXC_SAI1_TX_BCLK		0xd6
			MX8MQ_IOMUXC_SAI1_TXD0_SAI1_TX_DATA0		0xd6
			MX8MQ_IOMUXC_SAI1_TXD1_SAI1_TX_DATA1		0xd6
			MX8MQ_IOMUXC_SAI1_TXD2_SAI1_TX_DATA2		0xd6
			MX8MQ_IOMUXC_SAI1_TXD3_SAI1_TX_DATA3		0xd6
			MX8MQ_IOMUXC_SAI1_TXD4_SAI1_TX_DATA4		0xd6
			MX8MQ_IOMUXC_SAI1_TXD5_SAI1_TX_DATA5		0xd6
			MX8MQ_IOMUXC_SAI1_TXD6_SAI1_TX_DATA6		0xd6
			MX8MQ_IOMUXC_SAI1_TXD7_SAI1_TX_DATA7		0xd6
		>;
	};

	pinctrl_sai1_dsd: sai1grp_dsd {
		fsl,pins = <
			MX8MQ_IOMUXC_SAI1_MCLK_SAI1_MCLK		0xd6
			MX8MQ_IOMUXC_SAI1_TXFS_SAI1_TX_SYNC		0xd6
			MX8MQ_IOMUXC_SAI1_RXD7_SAI1_TX_DATA4		0xd6
			MX8MQ_IOMUXC_SAI1_TXC_SAI1_TX_BCLK		0xd6
			MX8MQ_IOMUXC_SAI1_TXD0_SAI1_TX_DATA0		0xd6
			MX8MQ_IOMUXC_SAI1_TXD1_SAI1_TX_DATA1		0xd6
			MX8MQ_IOMUXC_SAI1_TXD2_SAI1_TX_DATA2		0xd6
			MX8MQ_IOMUXC_SAI1_TXD3_SAI1_TX_DATA3		0xd6
			MX8MQ_IOMUXC_SAI1_TXD4_SAI1_TX_DATA4		0xd6
			MX8MQ_IOMUXC_SAI1_TXD5_SAI1_TX_DATA5		0xd6
			MX8MQ_IOMUXC_SAI1_TXD6_SAI1_TX_DATA6		0xd6
			MX8MQ_IOMUXC_SAI1_TXD7_SAI1_TX_DATA7		0xd6
		>;
	};

	pinctrl_sai5: sai5grp {
		fsl,pins = <
			MX8MQ_IOMUXC_SAI5_MCLK_SAI5_MCLK	0xd6
			MX8MQ_IOMUXC_SAI5_RXC_SAI5_RX_BCLK	0xd6
			MX8MQ_IOMUXC_SAI5_RXFS_SAI5_RX_SYNC	0xd6
			MX8MQ_IOMUXC_SAI5_RXD0_GPIO3_IO21	0x19
			MX8MQ_IOMUXC_SAI5_RXD1_GPIO3_IO22	0x19
			//MX8MQ_IOMUXC_SAI5_RXD2_GPIO3_IO23	0x19
			//MX8MQ_IOMUXC_SAI5_RXD3_GPIO3_IO24	0x19
		>;
	};

	pinctrl_spdif1: spdif1grp {
		fsl,pins = <
			MX8MQ_IOMUXC_SPDIF_RX_SPDIF1_IN		0xd6
		>;
	};

	pinctrl_typec: typecgrp {
		fsl,pins = <
			MX8MQ_IOMUXC_NAND_ALE_GPIO3_IO0		0x19
		>;
	};

	pinctrl_uart1: uart1grp {
		fsl,pins = <
			MX8MQ_IOMUXC_UART1_RXD_UART1_DCE_RX		0x49
			MX8MQ_IOMUXC_UART1_TXD_UART1_DCE_TX		0x49
			MX8MQ_IOMUXC_UART3_RXD_UART1_DCE_CTS_B		0x49
			MX8MQ_IOMUXC_UART3_TXD_UART1_DCE_RTS_B		0x49
		>;
	};

	pinctrl_uart2: uart2grp {
		fsl,pins = <
			MX8MQ_IOMUXC_UART2_RXD_UART2_DCE_RX		0x49
			MX8MQ_IOMUXC_UART2_TXD_UART2_DCE_TX		0x49
			MX8MQ_IOMUXC_UART4_RXD_UART2_DCE_CTS_B		0x49
//			MX8MQ_IOMUXC_UART4_TXD_UART2_DCE_RTS_B		0x49
			MX8MQ_IOMUXC_UART4_TXD_GPIO5_IO29		0x19
		>;
	};

	pinctrl_uart3: uart3grp {
		fsl,pins = <
			MX8MQ_IOMUXC_UART3_TXD_UART3_DCE_TX		0x49
			MX8MQ_IOMUXC_UART3_RXD_UART3_DCE_RX		0x49
			MX8MQ_IOMUXC_ECSPI1_MISO_UART3_DCE_CTS_B	0x49
			MX8MQ_IOMUXC_ECSPI1_SS0_UART3_DCE_RTS_B		0x49
			MX8MQ_IOMUXC_NAND_CLE_GPIO3_IO5			0x19
		>;
	};

	pinctrl_usdhc1: usdhc1grp {
		fsl,pins = <
			MX8MQ_IOMUXC_SD1_CLK_USDHC1_CLK			0x83
			MX8MQ_IOMUXC_SD1_CMD_USDHC1_CMD			0xc3
			MX8MQ_IOMUXC_SD1_DATA0_USDHC1_DATA0		0xc3
			MX8MQ_IOMUXC_SD1_DATA1_USDHC1_DATA1		0xc3
			MX8MQ_IOMUXC_SD1_DATA2_USDHC1_DATA2		0xc3
			MX8MQ_IOMUXC_SD1_DATA3_USDHC1_DATA3		0xc3
			MX8MQ_IOMUXC_SD1_DATA4_USDHC1_DATA4		0xc3
			MX8MQ_IOMUXC_SD1_DATA5_USDHC1_DATA5		0xc3
			MX8MQ_IOMUXC_SD1_DATA6_USDHC1_DATA6		0xc3
			MX8MQ_IOMUXC_SD1_DATA7_USDHC1_DATA7		0xc3
			MX8MQ_IOMUXC_SD1_STROBE_USDHC1_STROBE		0x83
			MX8MQ_IOMUXC_SD1_RESET_B_USDHC1_RESET_B		0xc1
		>;
	};

	pinctrl_usdhc1_100mhz: usdhc1-100grp {
		fsl,pins = <
			MX8MQ_IOMUXC_SD1_CLK_USDHC1_CLK			0x8d
			MX8MQ_IOMUXC_SD1_CMD_USDHC1_CMD			0xcd
			MX8MQ_IOMUXC_SD1_DATA0_USDHC1_DATA0		0xcd
			MX8MQ_IOMUXC_SD1_DATA1_USDHC1_DATA1		0xcd
			MX8MQ_IOMUXC_SD1_DATA2_USDHC1_DATA2		0xcd
			MX8MQ_IOMUXC_SD1_DATA3_USDHC1_DATA3		0xcd
			MX8MQ_IOMUXC_SD1_DATA4_USDHC1_DATA4		0xcd
			MX8MQ_IOMUXC_SD1_DATA5_USDHC1_DATA5		0xcd
			MX8MQ_IOMUXC_SD1_DATA6_USDHC1_DATA6		0xcd
			MX8MQ_IOMUXC_SD1_DATA7_USDHC1_DATA7		0xcd
			MX8MQ_IOMUXC_SD1_STROBE_USDHC1_STROBE		0x8d
			MX8MQ_IOMUXC_SD1_RESET_B_USDHC1_RESET_B		0xc1
		>;
	};

	pinctrl_usdhc1_200mhz: usdhc1-200grp {
		fsl,pins = <
			MX8MQ_IOMUXC_SD1_CLK_USDHC1_CLK			0x9f
			MX8MQ_IOMUXC_SD1_CMD_USDHC1_CMD			0xdf
			MX8MQ_IOMUXC_SD1_DATA0_USDHC1_DATA0		0xdf
			MX8MQ_IOMUXC_SD1_DATA1_USDHC1_DATA1		0xdf
			MX8MQ_IOMUXC_SD1_DATA2_USDHC1_DATA2		0xdf
			MX8MQ_IOMUXC_SD1_DATA3_USDHC1_DATA3		0xdf
			MX8MQ_IOMUXC_SD1_DATA4_USDHC1_DATA4		0xdf
			MX8MQ_IOMUXC_SD1_DATA5_USDHC1_DATA5		0xdf
			MX8MQ_IOMUXC_SD1_DATA6_USDHC1_DATA6		0xdf
			MX8MQ_IOMUXC_SD1_DATA7_USDHC1_DATA7		0xdf
			MX8MQ_IOMUXC_SD1_STROBE_USDHC1_STROBE		0x9f
			MX8MQ_IOMUXC_SD1_RESET_B_USDHC1_RESET_B		0xc1
		>;
	};

	pinctrl_usdhc2_gpio: usdhc2gpiogrp {
		fsl,pins = <
			MX8MQ_IOMUXC_SD2_CD_B_GPIO2_IO12		0x41
		>;
	};

	pinctrl_usdhc2: usdhc2grp {
		fsl,pins = <
			MX8MQ_IOMUXC_SD2_CLK_USDHC2_CLK			0x83
			MX8MQ_IOMUXC_SD2_CMD_USDHC2_CMD			0xc3
			MX8MQ_IOMUXC_SD2_DATA0_USDHC2_DATA0		0xc3
			MX8MQ_IOMUXC_SD2_DATA1_USDHC2_DATA1		0xc3
			MX8MQ_IOMUXC_SD2_DATA2_USDHC2_DATA2		0xc3
			MX8MQ_IOMUXC_SD2_DATA3_USDHC2_DATA3		0xc3
			MX8MQ_IOMUXC_GPIO1_IO04_USDHC2_VSELECT		0xc1
		>;
	};

	pinctrl_usdhc2_100mhz: usdhc2-100grp {
		fsl,pins = <
			MX8MQ_IOMUXC_SD2_CLK_USDHC2_CLK			0x85
			MX8MQ_IOMUXC_SD2_CMD_USDHC2_CMD			0xc5
			MX8MQ_IOMUXC_SD2_DATA0_USDHC2_DATA0		0xc5
			MX8MQ_IOMUXC_SD2_DATA1_USDHC2_DATA1		0xc5
			MX8MQ_IOMUXC_SD2_DATA2_USDHC2_DATA2		0xc5
			MX8MQ_IOMUXC_SD2_DATA3_USDHC2_DATA3		0xc5
			MX8MQ_IOMUXC_GPIO1_IO04_USDHC2_VSELECT		0xc1
		>;
	};

	pinctrl_usdhc2_200mhz: usdhc2-200grp {
		fsl,pins = <
			MX8MQ_IOMUXC_SD2_CLK_USDHC2_CLK			0x87
			MX8MQ_IOMUXC_SD2_CMD_USDHC2_CMD			0xc7
			MX8MQ_IOMUXC_SD2_DATA0_USDHC2_DATA0		0xc7
			MX8MQ_IOMUXC_SD2_DATA1_USDHC2_DATA1		0xc7
			MX8MQ_IOMUXC_SD2_DATA2_USDHC2_DATA2		0xc7
			MX8MQ_IOMUXC_SD2_DATA3_USDHC2_DATA3		0xc7
			MX8MQ_IOMUXC_GPIO1_IO04_USDHC2_VSELECT		0xc1
		>;
	};

	pinctrl_wdog: wdog1grp {
		fsl,pins = <
			MX8MQ_IOMUXC_GPIO1_IO02_WDOG1_WDOG_B		0xc6
		>;
	};
};

&vpu {
	status = "okay";
};

&vpu_v4l2 {
	status = "okay";
};

&gpu3d {
	assigned-clock-parents = <&clk IMX8MQ_GPU_PLL_OUT>,
				<&clk IMX8MQ_SYS2_PLL_1000M>,
				<&clk IMX8MQ_GPU_PLL_OUT>,
				<&clk IMX8MQ_GPU_PLL_OUT>;
	assigned-clock-rates = <800000000>, <1000000000>, <800000000>, <800000000>;
	status = "okay";
};

&ecspi1 {
	fsl,spi-num-chipselects = <1>;
	pinctrl-names = "default";
	pinctrl-0 = <&pinctrl_ecspi1 &pinctrl_ecspi1_cs>;
	cs-gpios = <&gpio5 9 GPIO_ACTIVE_HIGH>;
	status = "okay";

	tpi@0 {
		#address-cells = <1>;
		#size-cells = <1>;
		compatible = "tcg,tpm_tis-spi";
		spi-max-frequency = <20000000>;
		reg = <0>;
		status = "okay";
	};
};

&ecspi2 {
	fsl,spi-num-chipselects = <1>;
	pinctrl-names = "default";
	pinctrl-0 = <&pinctrl_ecspi2>,<&pinctrl_ecspi2_cs>;
	cs-gpios = <&gpio5 13 GPIO_ACTIVE_HIGH>,
		   <&gpio3 4 GPIO_ACTIVE_HIGH>;
	status = "okay";

	spidev@0 {
		#address-cells = <1>;
		#size-cells = <1>;
		compatible = "rohm,dh2228fv";
		spi-max-frequency = <20000000>;
		reg = <0>;
		status = "okay";
	};

	spidev@1 {
		#address-cells = <1>;
		#size-cells = <1>;
		compatible = "rohm,dh2228fv";
		spi-max-frequency = <20000000>;
		reg = <1>;
		status = "okay";
	};
};

&pwm3 {
	pinctrl-names = "default";
	pinctrl-0 = <&pinctrl_pwm3>;
	status = "okay";
};

&pwm4 {
	pinctrl-names = "default";
	pinctrl-0 = <&pinctrl_pwm4>;
	status = "okay";
};

&gpu3d {
	status = "okay";
};

&irqsteer {
	status = "okay";
};

&dcss {
	status = "okay";

	port@0 {
		dcss_out: endpoint {
			  remote-endpoint = <&hdmi_in>;
		};
	};
};

&hdmi {
	compatible = "cdn,imx8mq-hdmi";
	lane-mapping = <0xe4>;
	hdcp-config = <0x3>;
	status = "okay";
	port@1 {
		hdmi_in: endpoint {
			remote-endpoint = <&dcss_out>;
		};
	};
};

&thermal_zones {
        cpu-thermal {
                trips {
                        cpu-alert {
                                temperature = <95000>;
                        };

                        cpu-crit {
                                temperature = <105000>;
                        };
                };
        };
};

&lcdif {
	status = "okay";
	max-memory-bandwidth = <497829888>; /* 1920x1080-32@60.02 */
	port {
		lcdif_mipi_dsi: endpoint {
			remote-endpoint = <&mipi_dsi_in>;
		};
	};
};

&mipi_dsi {
	status = "okay";
	fsl,clock-drop-level = <2>;
	#address-cells = <1>;
	#size-cells = <0>;

	panel@0 {
		compatible = "simple-panel-dsi";
		reg = <0>;

		lkw070n13000-v2-exit-sequence = [
			05 64 02 28 00
			05 32 02 10 00
		];

		lkw070n13000-v2-init-sequence = [
			29 00 04 FF 98 81 03
			15 00 02 01 00
			15 00 02 02 00
			15 00 02 03 72
			15 00 02 04 00
			15 00 02 05 00
			15 00 02 06 09
			15 00 02 07 00
			15 00 02 08 00
			15 00 02 09 00
			15 00 02 0A 00
			15 00 02 0B 00
			15 00 02 0C 00
			15 00 02 0D 00
			15 00 02 0E 00
			15 00 02 0F 00
			15 00 02 10 00
			15 00 02 11 00
			15 00 02 12 00
			15 00 02 13 00
			15 00 02 14 00
			15 00 02 15 00
			15 00 02 16 00
			15 00 02 17 00
			15 00 02 18 00
			15 00 02 19 00
			15 00 02 1A 00
			15 00 02 1B 00
			15 00 02 1C 00
			15 00 02 1D 00
			15 00 02 1E 40
			15 00 02 1F 80
			15 00 02 20 05
			15 00 02 21 02
			15 00 02 22 00
			15 00 02 23 00
			15 00 02 24 00
			15 00 02 25 00
			15 00 02 26 00
			15 00 02 27 00
			15 00 02 28 33
			15 00 02 29 22
			15 00 02 2A 00
			15 00 02 2B 00
			15 00 02 2C 00
			15 00 02 2D 00
			15 00 02 2E 00
			15 00 02 2F 00
			15 00 02 30 00
			15 00 02 31 00
			15 00 02 32 00
			15 00 02 33 00
			15 00 02 34 04
			15 00 02 35 00
			15 00 02 36 00
			15 00 02 37 00
			15 00 02 38 3C
			15 00 02 39 00
			15 00 02 3A 00
			15 00 02 3B 00
			15 00 02 3C 00
			15 00 02 3D 00
			15 00 02 3E 00
			15 00 02 3F 00
			15 00 02 40 00
			15 00 02 41 00
			15 00 02 42 00
			15 00 02 43 00
			15 00 02 44 00
			15 00 02 50 10
			15 00 02 51 32
			15 00 02 52 54
			15 00 02 53 76
			15 00 02 54 98
			15 00 02 55 BA
			15 00 02 56 10
			15 00 02 57 32
			15 00 02 58 54
			15 00 02 59 76
			15 00 02 5A 98
			15 00 02 5B BA
			15 00 02 5C DC
			15 00 02 5D FE
			15 00 02 5E 00
			15 00 02 5F 01
			15 00 02 60 00
			15 00 02 61 15
			15 00 02 62 14
			15 00 02 63 0E
			15 00 02 64 0F
			15 00 02 65 0C
			15 00 02 66 0D
			15 00 02 67 06
			15 00 02 68 02
			15 00 02 69 02
			15 00 02 6A 02
			15 00 02 6B 02
			15 00 02 6C 02
			15 00 02 6D 02
			15 00 02 6E 07
			15 00 02 6F 02
			15 00 02 70 02
			15 00 02 71 02
			15 00 02 72 02
			15 00 02 73 02
			15 00 02 74 02
			15 00 02 75 01
			15 00 02 76 00
			15 00 02 77 14
			15 00 02 78 15
			15 00 02 79 0E
			15 00 02 7A 0F
			15 00 02 7B 0C
			15 00 02 7C 0D
			15 00 02 7D 06
			15 00 02 7E 02
			15 00 02 7F 02
			15 00 02 80 02
			15 00 02 81 02
			15 00 02 82 02
			15 00 02 83 02
			15 00 02 84 07
			15 00 02 85 02
			15 00 02 86 02
			15 00 02 87 02
			15 00 02 88 02
			15 00 02 89 02
			15 00 02 8A 02
			29 00 04 FF 98 81 04
			15 00 02 6E 2A
			15 00 02 6F 35
			15 00 02 3A 24
			15 00 02 8D 14
			15 00 02 87 BA
			15 00 02 26 76
			15 00 02 B2 D1
			15 00 02 B5 27
			15 00 02 31 75
			15 00 02 30 03
			15 00 02 3B 98
			15 00 02 35 1F
			15 00 02 33 14
			15 00 02 7A 0F
			15 00 02 38 01
			15 00 02 39 00
			29 00 04 FF 98 81 01
			15 00 02 22 0A
			15 00 02 31 00
			15 00 02 53 45
			15 00 02 55 4E
			15 00 02 50 C7
			15 00 02 51 C2
			15 00 02 60 25
			15 00 02 63 00
			15 00 02 a0 00
			15 00 02 A1 18
			15 00 02 A2 27
			15 00 02 A3 14
			15 00 02 A4 17
			15 00 02 A5 2A
			15 00 02 A6 1E
			15 00 02 A7 20
			15 00 02 A8 90
			15 00 02 A9 1C
			15 00 02 AA 28
			15 00 02 AB 84
			15 00 02 AC 1F
			15 00 02 AD 21
			15 00 02 AE 55
			15 00 02 AF 2A
			15 00 02 B0 2D
			15 00 02 B1 52
			15 00 02 B2 5C
			15 00 02 B3 23
			15 00 02 C0 00
			15 00 02 C1 18
			15 00 02 C2 27
			15 00 02 C3 14
			15 00 02 C4 17
			15 00 02 C5 2A
			15 00 02 C6 1E
			15 00 02 C7 20
			15 00 02 C8 90
			15 00 02 C9 1C
			15 00 02 CA 28
			15 00 02 CB 84
			15 00 02 CC 1F
			15 00 02 CD 21
			15 00 02 CE 55
			15 00 02 CF 2A
			15 00 02 D0 2D
			15 00 02 D1 52
			15 00 02 D2 5C
			15 00 02 D3 23
			29 00 04 FF 98 81 00
			15 00 02 35 00
			05 78 01 11
			05 32 01 29
		];


		rpi-init-sequence = [
				29 00 06 10 02 03 00 00 00
				29 00 06 64 01 0C 00 00 00
				29 00 06 68 01 0C 00 00 00
				29 00 06 44 01 00 00 00 00
				29 00 06 48 01 00 00 00 00
				29 00 06 14 01 15 00 00 00
				29 00 06 50 04 60 00 00 00
				29 00 06 20 04 52 01 10 00
				29 00 06 24 04 14 00 1A 00
				29 00 06 28 04 20 03 69 00
				29 00 06 2C 04 02 00 15 00
				29 00 06 30 04 E0 01 07 00
				29 00 06 34 04 01 00 00 00
				29 00 06 64 04 0F 04 00 00
				29 00 06 04 01 01 00 00 00
				29 00 06 04 02 01 00 00 00
		];
		powertip-exit-sequence = [
			05 14 01 28
			05 78 01 10
		];
		powertip-rev-a-init-sequence = [
			39 00 04 ff 98 81 03
			15 00 02 03 55
			15 00 02 04 13
			15 00 02 06 06
			15 00 02 07 01
			15 00 02 09 01
			15 00 02 0a 01
			15 00 02 0f 18
			15 00 02 10 18
			15 00 02 1e 44
			15 00 02 1f 80
			15 00 02 20 02
			15 00 02 21 03
			15 00 02 28 33
			15 00 02 29 03
			15 00 02 34 04
			15 00 02 38 01
			15 00 02 50 01
			15 00 02 51 23
			15 00 02 52 45
			15 00 02 53 67
			15 00 02 54 89
			15 00 02 55 ab
			15 00 02 56 01
			15 00 02 57 23
			15 00 02 58 45
			15 00 02 59 67
			15 00 02 5a 89
			15 00 02 5b ab
			15 00 02 5c cd
			15 00 02 5d ef
			15 00 02 5e 11
			15 00 02 5f 14
			15 00 02 60 15
			15 00 02 61 0f
			15 00 02 62 0d
			15 00 02 63 0e
			15 00 02 64 0c
			15 00 02 65 06
			15 00 02 66 02
			15 00 02 67 02
			15 00 02 68 02
			15 00 02 69 02
			15 00 02 6a 02
			15 00 02 6b 02
			15 00 02 6c 02
			15 00 02 6d 02
			15 00 02 6e 02
			15 00 02 6f 02
			15 00 02 70 02
			15 00 02 72 01
			15 00 02 73 08
			15 00 02 74 02
			15 00 02 75 14
			15 00 02 76 15
			15 00 02 77 0f
			15 00 02 78 0d
			15 00 02 79 0e
			15 00 02 7a 0c
			15 00 02 7b 08
			15 00 02 7c 02
			15 00 02 7d 02
			15 00 02 7e 02
			15 00 02 7f 02
			15 00 02 80 02
			15 00 02 81 02
			15 00 02 82 02
			15 00 02 83 02
			15 00 02 84 02
			15 00 02 85 02
			15 00 02 86 02
			15 00 02 88 01
			15 00 02 89 06
			15 00 02 8a 02
			39 00 04 ff 98 81 04
			15 00 02 6c 15
			15 00 02 6e 2a
			15 00 02 6f 33
			15 00 02 3a 24
			15 00 02 8d 14
			15 00 02 87 ba
			15 00 02 26 76
			15 00 02 b2 d1
			15 00 02 b5 d7
			15 00 02 35 1f
			39 00 04 ff 98 81 01
			15 00 02 22 0a
			15 00 02 53 72
			15 00 02 55 77
			15 00 02 50 a6
			15 00 02 51 a6
			15 00 02 60 30
			15 00 02 a0 08
			15 00 02 a1 1a
			15 00 02 a2 2a
			15 00 02 a3 14
			15 00 02 a4 17
			15 00 02 a5 2b
			15 00 02 a6 1d
			15 00 02 a7 20
			15 00 02 a8 9d
			15 00 02 a9 1c
			15 00 02 aa 29
			15 00 02 ab 8f
			15 00 02 ac 20
			15 00 02 ad 1f
			15 00 02 ae 4f
			15 00 02 af 23
			15 00 02 b0 29
			15 00 02 b1 56
			15 00 02 b2 66
			15 00 02 b3 39
			15 00 02 c0 08
			15 00 02 c1 1a
			15 00 02 c2 2a
			15 00 02 c3 15
			15 00 02 c4 17
			15 00 02 c5 2b
			15 00 02 c6 1d
			15 00 02 c7 20
			15 00 02 c8 9d
			15 00 02 c9 1d
			15 00 02 ca 29
			15 00 02 cb 8f
			15 00 02 cc 20
			15 00 02 cd 1f
			15 00 02 ce 4f
			15 00 02 cf 24
			15 00 02 d0 29
			15 00 02 d1 56
			15 00 02 d2 66
			15 00 02 d3 39
			39 00 04 ff 98 81 00
			15 00 02 35 00
			05 78 01 11
			05 78 01 29
		];
		powertip-rev-b-init-sequence = [
			39 00 04 FF 98 81 03
			15 00 02 01 00
			15 00 02 02 00
			15 00 02 03 73
			15 00 02 04 00
			15 00 02 05 00
			15 00 02 06 0A
			15 00 02 07 00
			15 00 02 08 00
			15 00 02 09 61
			15 00 02 0A 00
			15 00 02 0B 00
			15 00 02 0C 01
			15 00 02 0D 00
			15 00 02 0E 00
			15 00 02 0F 61
			15 00 02 10 61
			15 00 02 11 00
			15 00 02 12 00
			15 00 02 13 00
			15 00 02 14 00
			15 00 02 15 00
			15 00 02 16 00
			15 00 02 17 00
			15 00 02 18 00
			15 00 02 19 00
			15 00 02 1A 00
			15 00 02 1B 00
			15 00 02 1C 00
			15 00 02 1D 00
			15 00 02 1E 40
			15 00 02 1F 80
			15 00 02 20 06
			15 00 02 21 01
			15 00 02 22 00
			15 00 02 23 00
			15 00 02 24 00
			15 00 02 25 00
			15 00 02 26 00
			15 00 02 27 00
			15 00 02 28 33
			15 00 02 29 03
			15 00 02 2A 00
			15 00 02 2B 00
			15 00 02 2C 00
			15 00 02 2D 00
			15 00 02 2E 00
			15 00 02 2F 00
			15 00 02 30 00
			15 00 02 31 00
			15 00 02 32 00
			15 00 02 33 00
			15 00 02 34 04
			15 00 02 35 00
			15 00 02 36 00
			15 00 02 37 00
			15 00 02 38 3C
			15 00 02 39 00
			15 00 02 3A 00
			15 00 02 3B 00
			15 00 02 3C 00
			15 00 02 3D 00
			15 00 02 3E 00
			15 00 02 3F 00
			15 00 02 40 00
			15 00 02 41 00
			15 00 02 42 00
			15 00 02 43 00
			15 00 02 44 00
			15 00 02 50 10
			15 00 02 51 32
			15 00 02 52 54
			15 00 02 53 76
			15 00 02 54 98
			15 00 02 55 BA
			15 00 02 56 10
			15 00 02 57 32
			15 00 02 58 54
			15 00 02 59 76
			15 00 02 5A 98
			15 00 02 5B BA
			15 00 02 5C DC
			15 00 02 5D FE
			15 00 02 5E 00
			15 00 02 5F 0E
			15 00 02 60 0F
			15 00 02 61 0C
			15 00 02 62 0D
			15 00 02 63 06
			15 00 02 64 07
			15 00 02 65 02
			15 00 02 66 02
			15 00 02 67 02
			15 00 02 68 02
			15 00 02 69 01
			15 00 02 6A 00
			15 00 02 6B 02
			15 00 02 6C 15
			15 00 02 6D 14
			15 00 02 6E 02
			15 00 02 6F 02
			15 00 02 70 02
			15 00 02 71 02
			15 00 02 72 02
			15 00 02 73 02
			15 00 02 74 02
			15 00 02 75 0E
			15 00 02 76 0F
			15 00 02 77 0C
			15 00 02 78 0D
			15 00 02 79 06
			15 00 02 7A 07
			15 00 02 7B 02
			15 00 02 7C 02
			15 00 02 7D 02
			15 00 02 7E 02
			15 00 02 7F 01
			15 00 02 80 00
			15 00 02 81 02
			15 00 02 82 14
			15 00 02 83 15
			15 00 02 84 02
			15 00 02 85 02
			15 00 02 86 02
			15 00 02 87 02
			15 00 02 88 02
			15 00 02 89 02
			15 00 02 8A 02
			39 00 04 FF 98 81 04
			15 00 02 6C 15
			15 00 02 6E 2A
			15 00 02 6F 33
			15 00 02 3B 98
			15 00 02 3A 94
			15 00 02 8D 14
			15 00 02 87 BA
			15 00 02 26 76
			15 00 02 B2 D1
			15 00 02 B5 06
			15 00 02 38 01
			15 00 02 39 00
			39 00 04 FF 98 81 01
			15 00 02 22 0A
			15 00 02 31 00
			15 00 02 53 7D
			15 00 02 55 8F
			15 00 02 40 33
			15 00 02 50 96
			15 00 02 51 96
			15 00 02 60 23
			15 00 02 A0 08
			15 00 02 A1 1D
			15 00 02 A2 2A
			15 00 02 A3 10
			15 00 02 A4 15
			15 00 02 A5 28
			15 00 02 A6 1C
			15 00 02 A7 1D
			15 00 02 A8 7E
			15 00 02 A9 1D
			15 00 02 AA 29
			15 00 02 AB 6B
			15 00 02 AC 1A
			15 00 02 AD 18
			15 00 02 AE 4B
			15 00 02 AF 20
			15 00 02 B0 27
			15 00 02 B1 50
			15 00 02 B2 64
			15 00 02 B3 39
			15 00 02 C0 08
			15 00 02 C1 1D
			15 00 02 C2 2A
			15 00 02 C3 10
			15 00 02 C4 15
			15 00 02 C5 28
			15 00 02 C6 1C
			15 00 02 C7 1D
			15 00 02 C8 7E
			15 00 02 C9 1D
			15 00 02 CA 29
			15 00 02 CB 6B
			15 00 02 CC 1A
			15 00 02 CD 18
			15 00 02 CE 4B
			15 00 02 CF 20
			15 00 02 D0 27
			15 00 02 D1 50
			15 00 02 D2 64
			15 00 02 D3 39
			39 00 04 ff 98 81 00
			15 00 02 35 00
			05 78 01 11
			05 78 01 29
		];

		rpi-display-timings {
			native-mode = <&timing2>;

			timing2: timing2 {
				clock-frequency = <40000000>;
				hactive = <800>;
				vactive = <480>;
				hfront-porch = <60>;
				hsync-len = <20>;
				hback-porch = <26>;
				vfront-porch = <223>;
				vsync-len = <3>;
				vback-porch = <19>;
				hsync-active = <0>;
				vsync-active = <0>;
				de-active = <0>;
				pixelclk-active = <0>;
			};
		};

		powertip-display-timings {
			native-mode = <&timing1>;

			timing1: timing1 {
				clock-frequency = <62000000>;
				hactive = <720>;
				vactive = <1280>;
				hfront-porch = <10>;
				hsync-len = <20>;
				hback-porch = <30>;
				vfront-porch = <10>;
				vsync-len = <10>;
				vback-porch = <20>;
				hsync-active = <0>;
				vsync-active = <0>;
				de-active = <0>;
				pixelclk-active = <0>;
			};
		};

		port {
			panel_in: endpoint {
				remote-endpoint = <&mipi_dsi_out>;
			};
		};
	};

	ports {
		#address-cells = <1>;
		#size-cells = <0>;

		port@0 {
			#address-cells = <1>;
			#size-cells = <0>;
			reg = <0>;
			mipi_dsi_in: endpoint@0 {
				reg = <0>;
				remote-endpoint = <&lcdif_mipi_dsi>;
			};
		};

		port@1 {
			reg = <1>;
			mipi_dsi_out: endpoint {
				remote-endpoint = <&panel_in>;
			};
		};
	};
};

&dphy {
	status = "okay";
};
